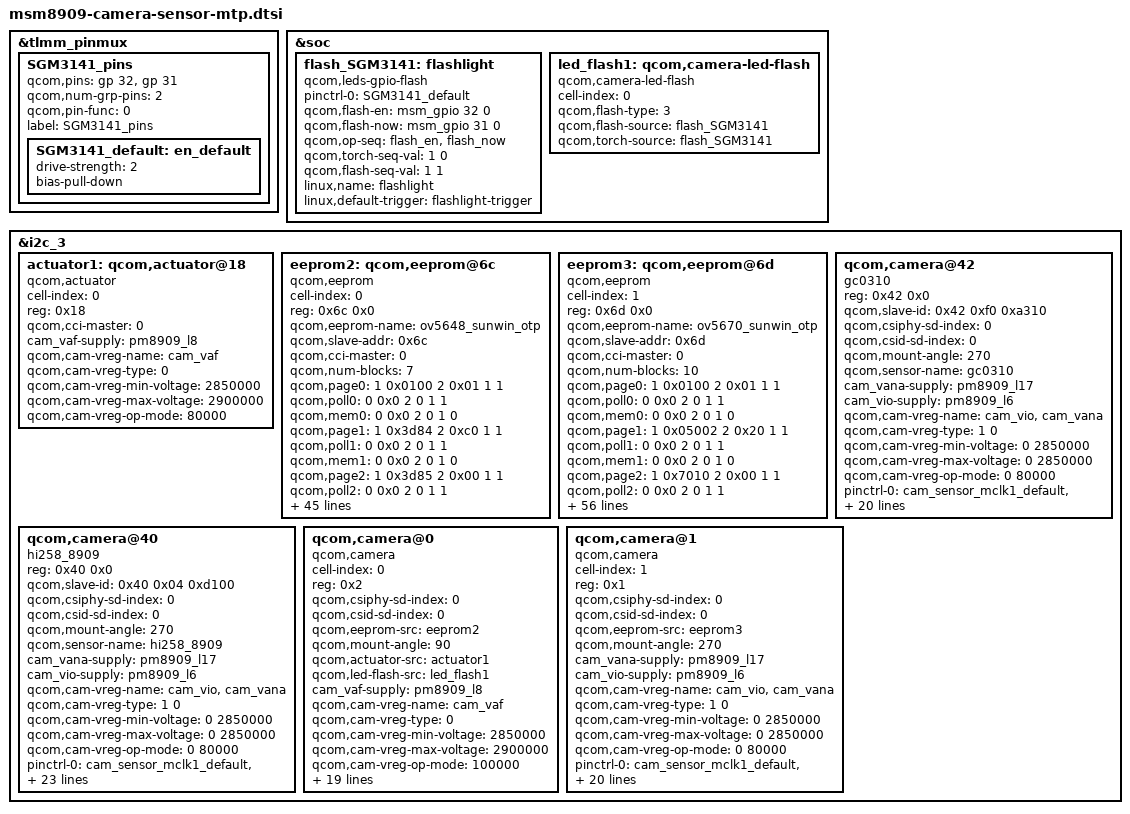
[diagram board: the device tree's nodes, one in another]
/*
 * Copyright (c) 2014, The Linux Foundation. All rights reserved.
 *
 * This program is free software; you can redistribute it and/or modify
 * it under the terms of the GNU General Public License version 2 and
 * only version 2 as published by the Free Software Foundation.
 *
 * This program is distributed in the hope that it will be useful,
 * but WITHOUT ANY WARRANTY; without even the implied warranty of
 * MERCHANTABILITY or FITNESS FOR A PARTICULAR PURPOSE.  See the
 * GNU General Public License for more details.
 */

&tlmm_pinmux {
	SGM3141_pins {
		qcom,pins = <&gp 32>, <&gp 31>;
		qcom,num-grp-pins = <2>;
		qcom,pin-func = <0>;
		label = "SGM3141_pins";
		SGM3141_default: en_default {
		drive-strength = <2>;
		bias-pull-down;
		};
	};
};

&soc {
	flash_SGM3141:flashlight {
		compatible = "qcom,leds-gpio-flash";
		status = "okay";
		pinctrl-names = "flash_default";
		pinctrl-0 = <&SGM3141_default>;
		qcom,flash-en = <&msm_gpio 32 0>;
		qcom,flash-now = <&msm_gpio 31 0>;
		qcom,op-seq = "flash_en", "flash_now";
		qcom,torch-seq-val = <1 0>;
		qcom,flash-seq-val = <1 1>;
		linux,name = "flashlight";
		linux,default-trigger = "flashlight-trigger";
	};
	led_flash1: qcom,camera-led-flash {
		cell-index = <0>;
		compatible = "qcom,camera-led-flash";
		qcom,flash-type = <3>;
		qcom,flash-source = <&flash_SGM3141>;
		qcom,torch-source = <&flash_SGM3141>;
	};
};

&i2c_3 {

	actuator1: qcom,actuator@18 {
		cell-index = <0>;
		reg = <0x18>;
		compatible = "qcom,actuator";
		qcom,cci-master = <0>;
		cam_vaf-supply = <&pm8909_l8>;
		qcom,cam-vreg-name = "cam_vaf";
		qcom,cam-vreg-type = <0>;
		qcom,cam-vreg-min-voltage = <2850000>;
		qcom,cam-vreg-max-voltage = <2900000>;
		qcom,cam-vreg-op-mode = <80000>;
	};

	// OV5648
        eeprom2: qcom,eeprom@6c{
                cell-index = <0>;
                reg = <0x6c 0x0>;
                qcom,eeprom-name = "ov5648_sunwin_otp";
                compatible = "qcom,eeprom";
                qcom,slave-addr = <0x6c>;
                qcom,cci-master = <0>;
                qcom,num-blocks = <7>;
    
                qcom,page0 = <1 0x0100 2 0x01 1 1>; 
                qcom,poll0 = <0 0x0 2 0 1 1>; 
                qcom,mem0 = <0 0x0 2 0 1 0>; 

                qcom,page1 = <1 0x3d84 2 0xc0 1 1>; 
                qcom,poll1 = <0 0x0 2 0 1 1>; 
                qcom,mem1 = <0 0x0 2 0 1 0>; 
            
                qcom,page2 = <1 0x3d85 2 0x00 1 1>; 
                qcom,poll2 = <0 0x0 2 0 1 1>; 
                qcom,mem2 = <0 0x0 2 0 1 0>; 
            
                qcom,page3 = <1 0x3d86 2 0x0f 1 1>; 
                qcom,pageen3 = <1 0x3d81 2 0x01 1 10>;
                qcom,poll3 = <0 0x0 2 0 1 1>; 
                qcom,mem3 = <16 0x3d00 2 0 1 0>;

                qcom,page4 = <1 0x3d84 2 0xc0 1 1>;
                qcom,poll4 = <0 0x0 2 0 1 1>;
                qcom,mem4 = <0 0x0 2 0 1 0>;
            
                qcom,page5 = <1 0x3d85 2 0x10 1 1>;
                qcom,poll5 = <0 0x0 2 0 1 1>;
                qcom,mem5 = <0 0x0 2 0 1 0>;
            
                qcom,page6 = <1 0x3d86 2 0x1f 1 1>;
                qcom,pageen6 = <1 0x3d81 2 0x01 1 10>;
                qcom,poll6 = <0 0x0 2 0 1 1>;
                qcom,mem6 = <16 0x3d00 2 0 1 0>;

		cam_vaf-supply = <&pm8909_l8>;
		qcom,cam-vreg-name = "cam_vaf";
		qcom,cam-vreg-type = <0>;
		qcom,cam-vreg-min-voltage = <2850000>;
		qcom,cam-vreg-max-voltage = <2900000>;
		qcom,cam-vreg-op-mode = <100000>;
		pinctrl-names = "cam_default", "cam_suspend";
		pinctrl-0 = <&cam_sensor_mclk0_default
				&cam_sensor_rear_default>;
		pinctrl-1 = <&cam_sensor_mclk0_sleep &cam_sensor_rear_sleep>;
		gpios = <&msm_gpio 26 0>,
			<&msm_gpio 35 0>,
			<&msm_gpio 34 0>,
			<&msm_gpio 23 0>,
			<&msm_gpio 20 0>;
		qcom,gpio-reset = <1>;
		qcom,gpio-standby = <2>;
		qcom,gpio-vana = <3>;
		qcom,gpio-vdig = <4>;
		qcom,gpio-req-tbl-num = <0 1 2 3 4>;
		qcom,gpio-req-tbl-flags = <1 0 0 0 0>;
		qcom,gpio-req-tbl-label = "CAMIF_MCLK",
			"CAM_RESET1",
			"CAM_STANDBY",
			"CAM_VANA",
			"CAM_VDIG";
                
		qcom,cam-power-seq-type = "sensor_clk", 
			"sensor_gpio", // Jiangde
			"sensor_gpio",
			"sensor_gpio",
			"sensor_gpio";
		qcom,cam-power-seq-val = "sensor_cam_mclk", 
			"sensor_gpio_reset", // Jiangde
			"sensor_gpio_standby",
			"sensor_gpio_vana",
			"sensor_gpio_vdig" ;
		qcom,cam-power-seq-cfg-val = <24000000 1 1 1 1>;
		qcom,cam-power-seq-delay = <5 10 10 10 10>;

		clocks = <&clock_gcc clk_mclk0_clk_src>,
				<&clock_gcc clk_gcc_camss_mclk0_clk>;
		clock-names = "cam_src_clk", "cam_clk";
	};

      //ov5670
      eeprom3: qcom,eeprom@6d{
                cell-index = <1>;
                reg = <0x6d 0x0>;
                qcom,eeprom-name = "ov5670_sunwin_otp";
                compatible = "qcom,eeprom";
                qcom,slave-addr = <0x6d>;
                qcom,cci-master = <0>;
                qcom,num-blocks = <10>;

    		qcom,page0 = <1 0x0100 2 0x01 1 1>;
		qcom,poll0 = <0 0x0 2 0 1 1>;
		qcom,mem0 = <0 0x0 2 0 1 0>;

                qcom,page1 = <1 0x05002 2 0x20 1 1>; 
                qcom,poll1 = <0 0x0 2 0 1 1>; 
                qcom,mem1 = <0 0x0 2 0 1 0>; 

		qcom,page2 = <1 0x7010 2 0x00 1 1>;
                qcom,poll2 = <0 0x0 2 0 1 1>; 
                qcom,mem2 = <0 0x0 2 0 1 0>; 

		qcom,page3 = <1 0x3d84 2 0xc0 1 1>; 
		qcom,poll3 = <0 0x0 2 0 1 1>; 
		qcom,mem3 = <0 0x0 2 0 1 0>;

		qcom,page4 = <1 0x3d88 2 0x70 1 1>; 
		qcom,poll4 = <0 0x0 2 0 1 1>; 
		qcom,mem4 = <0 0x0 2 0 1 0>;

		qcom,page5 = <1 0x3d89 2 0x10 1 1>; 
		qcom,poll5 = <0 0x0 2 0 1 1>; 
		qcom,mem5 = <0 0x0 2 0 1 0>;

		qcom,page6 = <1 0x3d8a 2 0x70 1 1>; 
		qcom,poll6 = <0 0x0 2 0 1 1>; 
		qcom,mem6 = <0 0x0 2 0 1 0>;

		qcom,page7 = <1 0x3d8b 2 0x29 1 1>; 
		qcom,poll7 = <0 0x0 2 0 1 1>; 
		qcom,mem7 = <0 0x0 2 0 1 0>;


		qcom,page8 = <1 0x3d81 2 0x01 1 2>;
		qcom,poll8 = <0 0x0 2 0 1 1>; 
		qcom,mem8 = <26 0x7010 2 0 1 1>;

                qcom,page9 = <1 0x05002 2 0x28 1 1>; 
                qcom,poll9 = <0 0x0 2 0 1 1>; 
                qcom,mem9 = <0 0x0 2 0 1 0>; 

		cam_vana-supply = <&pm8909_l17>;
		cam_vio-supply = <&pm8909_l6>;
		qcom,cam-vreg-name = "cam_vio", "cam_vana";
		qcom,cam-vreg-type = <1 0>;
		qcom,cam-vreg-min-voltage = <0 2850000>;
		qcom,cam-vreg-max-voltage = <0 2850000>;
		qcom,cam-vreg-op-mode = <0 80000>;
		pinctrl-names = "cam_default", "cam_suspend";
		pinctrl-0 = <&cam_sensor_mclk1_default
				&cam_sensor_front_default>;
		pinctrl-1 = <&cam_sensor_mclk1_sleep &cam_sensor_front_sleep>;
		gpios = <&msm_gpio 27 0>,
			<&msm_gpio 28 0>,
			<&msm_gpio 33 0>,
			<&msm_gpio 91 0>,
			<&msm_gpio 92 0>,
			<&msm_gpio 73 0>;
		qcom,gpio-reset = <1>;
		qcom,gpio-standby = <2>;
		qcom,gpio-vdig = <3>;
		qcom,gpio-vana = <4>;
		qcom,gpio-vio = <5>;
		qcom,gpio-req-tbl-num = <0 1 2 3 4 5>;
		qcom,gpio-req-tbl-flags = <1 0 0 0 0 0>;
		qcom,gpio-req-tbl-label = "CAMIF_MCLK",
					"CAM_RESET",
					"CAM_STANDBY",
					"CAM_VDIG",
					"CAM_VANA",
					"CAM_VIO";
                
		qcom,cam-power-seq-type = "sensor_clk", 
			"sensor_gpio", // Jiangde
			"sensor_gpio",
			"sensor_gpio",
			"sensor_gpio",
			"sensor_gpio";
		qcom,cam-power-seq-val = "sensor_cam_mclk", 
			"sensor_gpio_reset", // Jiangde
			"sensor_gpio_standby",
			"sensor_gpio_vdig",
			"sensor_gpio_vana",
			"sensor_gpio_vio";
		qcom,cam-power-seq-cfg-val = <24000000 1 1 1 1 1>;
		qcom,cam-power-seq-delay = <5 10 10 10 10 10>;

		clocks = <&clock_gcc clk_mclk1_clk_src>,
				<&clock_gcc clk_gcc_camss_mclk1_clk>;
		clock-names = "cam_src_clk", "cam_clk";
	};
	qcom,camera@42 {
		compatible = "gc0310";
		reg = <0x42 0x0>;
		qcom,slave-id = <0x42 0xf0 0xa310>;
		qcom,csiphy-sd-index = <0>;
		qcom,csid-sd-index = <0>;
		qcom,mount-angle = <270>;
		qcom,sensor-name = "gc0310";
		cam_vana-supply = <&pm8909_l17>;
		cam_vio-supply = <&pm8909_l6>;
		qcom,cam-vreg-name = "cam_vio", "cam_vana";
		//qcom,cam-custom-vreg-name = "cam_vio", "cam_vana";
		qcom,cam-vreg-type = <1 0>;
		qcom,cam-vreg-min-voltage = <0 2850000>;
		qcom,cam-vreg-max-voltage = <0 2850000>;
		qcom,cam-vreg-op-mode = <0 80000>;
		pinctrl-names = "cam_default", "cam_suspend";
		pinctrl-0 = <&cam_sensor_mclk1_default
				&cam_sensor_front_default>;
		pinctrl-1 = <&cam_sensor_mclk1_sleep &cam_sensor_front_sleep>;
		gpios = <&msm_gpio 27 0>,
			<&msm_gpio 28 0>,
			<&msm_gpio 33 0>;
		qcom,gpio-reset = <1>;
		qcom,gpio-standby = <2>;
		qcom,gpio-req-tbl-num = <0 1 2>;
		qcom,gpio-req-tbl-flags = <1 0 0>;
		qcom,gpio-req-tbl-label = "CAMIF_MCLK",
					"CAM_RESET",
					"CAM_STANDBY";
		qcom,gpio-set-tbl-num = <1 1>;
		qcom,gpio-set-tbl-flags = <0 2>;
		qcom,gpio-set-tbl-delay = <1000 4000>;
		qcom,csi-lane-assign = <0x0004>;
		qcom,csi-lane-mask = <0x18>;
		qcom,sensor-position = <1>;
		qcom,sensor-mode = <0>;
		qcom,cci-master = <0>;
		clocks = <&clock_gcc clk_mclk1_clk_src>,
				<&clock_gcc clk_gcc_camss_mclk1_clk>;
		clock-names = "cam_src_clk", "cam_clk";
	};

	qcom,camera@40 {
		compatible = "hi258_8909";
		reg = <0x40 0x0>;
		qcom,slave-id = <0x40 0x04 0xd100>;
		qcom,csiphy-sd-index = <0>;
		qcom,csid-sd-index = <0>;
		qcom,mount-angle = <270>;
		qcom,sensor-name = "hi258_8909";
		cam_vana-supply = <&pm8909_l17>;
		cam_vio-supply = <&pm8909_l6>;
		qcom,cam-vreg-name = "cam_vio", "cam_vana";
		//qcom,cam-custom-vreg-name = "cam_vio", "cam_vana";
		qcom,cam-vreg-type = <1 0>;
		qcom,cam-vreg-min-voltage = <0 2850000>;
		qcom,cam-vreg-max-voltage = <0 2850000>;
		qcom,cam-vreg-op-mode = <0 80000>;
		pinctrl-names = "cam_default", "cam_suspend";
		pinctrl-0 = <&cam_sensor_mclk1_default
				&cam_sensor_front_default>;
		pinctrl-1 = <&cam_sensor_mclk1_sleep &cam_sensor_front_sleep>;
		gpios = <&msm_gpio 27 0>,
			<&msm_gpio 28 0>,
			<&msm_gpio 33 0>,
			<&msm_gpio 91 0>,
			<&msm_gpio 92 0>,
			<&msm_gpio 73 0>;
		qcom,gpio-reset = <1>;
		qcom,gpio-standby = <2>;
		qcom,gpio-vdig = <3>;
		qcom,gpio-vana = <4>;
		qcom,gpio-vio = <5>;
		qcom,gpio-req-tbl-num = <0 1 2 3 4 5>;
		qcom,gpio-req-tbl-flags = <1 0 0 0 0 0>;
		qcom,gpio-req-tbl-label = "CAMIF_MCLK",
					"CAM_RESET",
					"CAM_STANDBY",
					"CAM_VDIG",
					"CAM_VANA",
					"CAM_VIO";
		qcom,gpio-set-tbl-delay = <1000 4000>;
		qcom,csi-lane-assign = <0x0004>;
		qcom,csi-lane-mask = <0x18>;
		qcom,sensor-position = <1>;
		qcom,sensor-mode = <0>;
		qcom,cci-master = <0>;
		clocks = <&clock_gcc clk_mclk1_clk_src>,
				<&clock_gcc clk_gcc_camss_mclk1_clk>;
		clock-names = "cam_src_clk", "cam_clk";
	};
	qcom,camera@0 {
		cell-index = <0>;
		compatible = "qcom,camera";
		reg = <0x2>;
		qcom,csiphy-sd-index = <0>;
		qcom,csid-sd-index = <0>;
		qcom,eeprom-src = <&eeprom2>;
		qcom,mount-angle = <90>;
		qcom,actuator-src = <&actuator1>;
		qcom,led-flash-src = <&led_flash1>;
		cam_vaf-supply = <&pm8909_l8>;
		qcom,cam-vreg-name = "cam_vaf";
		qcom,cam-vreg-type = <0>;
		qcom,cam-vreg-min-voltage = <2850000>;
		qcom,cam-vreg-max-voltage = <2900000>;
		qcom,cam-vreg-op-mode = <100000>;
		pinctrl-names = "cam_default", "cam_suspend";
		pinctrl-0 = <&cam_sensor_mclk0_default
				&cam_sensor_rear_default>;
		pinctrl-1 = <&cam_sensor_mclk0_sleep &cam_sensor_rear_sleep>;
		gpios = <&msm_gpio 26 0>,
			<&msm_gpio 35 0>,
			<&msm_gpio 34 0>,
			<&msm_gpio 23 0>,
			<&msm_gpio 20 0>;
		qcom,gpio-reset = <1>;
		qcom,gpio-standby = <2>;
		qcom,gpio-vana = <3>;
		qcom,gpio-vdig = <4>;
		qcom,gpio-req-tbl-num = <0 1 2 3 4>;
		qcom,gpio-req-tbl-flags = <1 0 0 0 0>;
		qcom,gpio-req-tbl-label = "CAMIF_MCLK",
			"CAM_RESET1",
			"CAM_STANDBY",
			"CAM_VANA",
			"CAM_VDIG";
		qcom,sensor-position = <0>;
		qcom,sensor-mode = <0>;
		qcom,cci-master = <0>;
		status = "ok";
		clocks = <&clock_gcc clk_mclk0_clk_src>,
				<&clock_gcc clk_gcc_camss_mclk0_clk>;
		clock-names = "cam_src_clk", "cam_clk";
	};

	qcom,camera@1 {
		cell-index = <1>;
		compatible = "qcom,camera";
		reg = <0x1>;
		qcom,csiphy-sd-index = <0>;
		qcom,csid-sd-index = <0>;
		qcom,eeprom-src = <&eeprom3>;
		qcom,mount-angle = <270>;
		cam_vana-supply = <&pm8909_l17>;
		cam_vio-supply = <&pm8909_l6>;
		qcom,cam-vreg-name = "cam_vio", "cam_vana";
		qcom,cam-vreg-type = <1 0>;
		qcom,cam-vreg-min-voltage = <0 2850000>;
		qcom,cam-vreg-max-voltage = <0 2850000>;
		qcom,cam-vreg-op-mode = <0 80000>;
		pinctrl-names = "cam_default", "cam_suspend";
		pinctrl-0 = <&cam_sensor_mclk1_default
				&cam_sensor_front_default>;
		pinctrl-1 = <&cam_sensor_mclk1_sleep &cam_sensor_front_sleep>;
		gpios = <&msm_gpio 27 0>,
			<&msm_gpio 28 0>,
			<&msm_gpio 33 0>,
			<&msm_gpio 91 0>,
			<&msm_gpio 92 0>,
			<&msm_gpio 73 0>;
		qcom,gpio-reset = <1>;
		qcom,gpio-standby = <2>;
		qcom,gpio-vdig = <3>;
		qcom,gpio-vana = <4>;
		qcom,gpio-vio = <5>;
		qcom,gpio-req-tbl-num = <0 1 2 3 4 5>;
		qcom,gpio-req-tbl-flags = <1 0 0 0 0 0>;
		qcom,gpio-req-tbl-label = "CAMIF_MCLK",
					"CAM_RESET",
					"CAM_STANDBY",
					"CAM_VDIG",
					"CAM_VANA",
					"CAM_VIO";
		qcom,sensor-position = <1>;
		qcom,sensor-mode = <0>;
		qcom,cci-master = <0>;
		status = "ok";
		clocks = <&clock_gcc clk_mclk1_clk_src>,
				<&clock_gcc clk_gcc_camss_mclk1_clk>;
		clock-names = "cam_src_clk", "cam_clk";
	};
};
